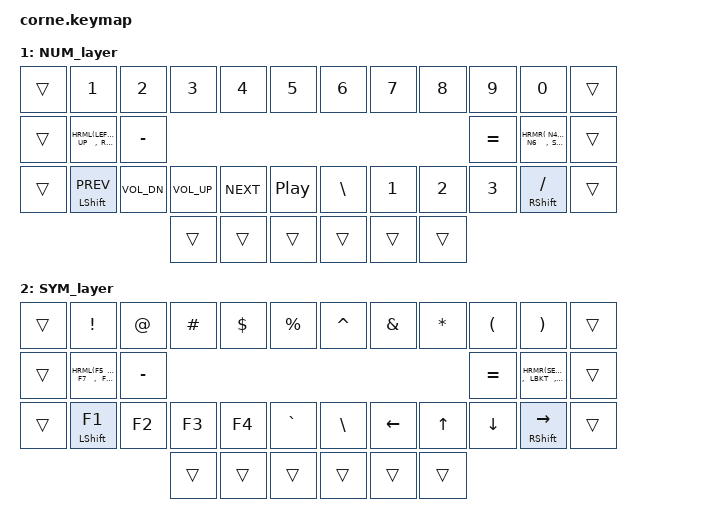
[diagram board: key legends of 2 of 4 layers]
// Copyright (c) 2022 The ZMK Contributors
// SPDX-License-Identifier: MIT

#include <behaviors.dtsi>
#include <dt-bindings/zmk/keys.h>
#include <dt-bindings/zmk/bt.h>



#define NUM 1
#define SYM 2
#define FNC 3


// funciones para acceso con hold ant tap
//#define HRML(k1,k2,k3,k4) &ht LSHFT k1  &ht LALT  k2  &ht LGUI  k3  &ht LCTRL  k4
//#define HRMR(k1,k2,k3,k4) &ht RCTRL  k1 &ht RGUI k2  &ht RALT k3  &ht RSHFT  k4

#define HRML(k1,k2,k3,k4) &ht LSHFT k1  &ht LCTRL  k2  &ht LALT  k3  &ht LGUI  k4
#define HRMR(k1,k2,k3,k4) &ht RGUI  k1 &ht RALT k2  &ht RCTRL k3  &ht RSHFT  k4

#define CAGL(k1,k2,k3) &ht LCTRL k1  &ht LALT k2  &ht LGUI  k3
#define CAGR(k1,k2,k3) &ht LGUI  k1  &ht LALT k2  &ht LCTRL  k3

// === Macros para acentos y ñ (macOS U.S.) ===
//1. Configuración de Tap Dance
/ {
    behaviors {
        // Define un comportamiento de Tap Dance para cada vocal y la ñ
        td_a: tap_dance_acute_a {
            compatible = "zmk,behavior-tap-dance";
            #binding-cells = <0>;
            tapping-term-ms = <250>; // Tiempo máximo entre taps
            bindings = <&kp A>, <&a_acute>; // 1 tap: a | 2 taps: á
        };
        // Tap Dance para A/Á (mayúsculas)
        td_MA: tap_dance_acute_MA {
            compatible = "zmk,behavior-tap-dance";
            #binding-cells = <0>;
            tapping-term-ms = <250>;
            bindings = <&kp LS(A)>, <&MA_acute>; // 1 tap: A | 2 taps: Á
        };
        td_e: tap_dance_acute_e {
            compatible = "zmk,behavior-tap-dance";
            #binding-cells = <0>;
            tapping-term-ms = <200>;
            bindings = <&kp E>, <&e_acute>;
        };
        // Tap Dance para E (mayúsculas)
        td_ME: tap_dance_acute_ME {
            compatible = "zmk,behavior-tap-dance";
            #binding-cells = <0>;
            tapping-term-ms = <200>;
            bindings = <&kp LS(E)>, <&ME_acute>;
        };
        td_i: tap_dance_acute_i {
            compatible = "zmk,behavior-tap-dance";
            #binding-cells = <0>;
            tapping-term-ms = <200>;
            bindings = <&kp I>, <&i_acute>;
        };
        // Tap Dance para I (mayúsculas)
        td_MI: tap_dance_acute_MI {
            compatible = "zmk,behavior-tap-dance";
            #binding-cells = <0>;
            tapping-term-ms = <200>;
            bindings = <&kp LS(I)>, <&MI_acute>;
        };
        td_o: tap_dance_acute_o {
            compatible = "zmk,behavior-tap-dance";
            #binding-cells = <0>;
            tapping-term-ms = <200>;
            bindings = <&kp O>, <&o_acute>;
        };
        // Tap Dance para O (mayúsculas)
        td_MO: tap_dance_acute_MO {
            compatible = "zmk,behavior-tap-dance";
            #binding-cells = <0>;
            tapping-term-ms = <200>;
            bindings = <&kp LS(O)>, <&MO_acute>;
        };
        td_u: tap_dance_acute_u {
            compatible = "zmk,behavior-tap-dance";
            #binding-cells = <0>;
            tapping-term-ms = <200>;
            bindings = <&kp U>, <&u_acute>;
        };
        // Tap Dance para U (mayúsculas)
        td_MU: tap_dance_acute_MU {
            compatible = "zmk,behavior-tap-dance";
            #binding-cells = <0>;
            tapping-term-ms = <200>;
            bindings = <&kp LS(U)>, <&MU_acute>;
        };
        td_n: tap_dance_tilde_n {
            compatible = "zmk,behavior-tap-dance";
            #binding-cells = <0>;
            tapping-term-ms = <200>;
            bindings = <&kp N>, <&n_tilde>; // 1 tap: n | 2 taps: ñ
        };
        // Tap Dance para N (mayúsculas)
        td_MN: tap_dance_acute_MN {
            compatible = "zmk,behavior-tap-dance";
            #binding-cells = <0>;
            tapping-term-ms = <200>;
            bindings = <&kp LS(N)>, <&MN_acute>;
        };
    };
};

//2. Define las macros para acentos y ñ
/ {
    macros {
        // Macro para á (Alt + E + A)
        a_acute: a_acute {
            compatible = "zmk,behavior-macro";
            #binding-cells = <0>;
            bindings = <&kp LA(E)>, <&kp A>;
        };
        // Macro para Á (Alt + E + Shift + a)
        MA_acute: MA_acute {
            compatible = "zmk,behavior-macro";
            #binding-cells = <0>;
            bindings = <&kp LA(E)>, <&kp LS(A)>; // LS = Left Shift
        };
        // Macro para é (Alt + E + E)
        e_acute: e_acute {
            compatible = "zmk,behavior-macro";
            #binding-cells = <0>;
            bindings = <&kp LA(E)>, <&kp E>;
        };
        // Macro para E 
        ME_acute: ME_acute {
            compatible = "zmk,behavior-macro";
            #binding-cells = <0>;
            bindings = <&kp LA(E)>, <&kp LS(E)>; // LS = Left Shift
        };
        // Macro para í (Alt + E + I)
        i_acute: i_acute {
            compatible = "zmk,behavior-macro";
            #binding-cells = <0>;
            bindings = <&kp LA(E)>, <&kp I>;
        };
        // Macro para I
        MI_acute: MI_acute {
            compatible = "zmk,behavior-macro";
            #binding-cells = <0>;
            bindings = <&kp LA(E)>, <&kp LS(I)>; // LS = Left Shift
        };
        // Macro para ó (Alt + E + O)
        o_acute: o_acute {
            compatible = "zmk,behavior-macro";
            #binding-cells = <0>;
            bindings = <&kp LA(E)>, <&kp O>;
        };
        // Macro para O
        MO_acute: MO_acute {
            compatible = "zmk,behavior-macro";
            #binding-cells = <0>;
            bindings = <&kp LA(E)>, <&kp LS(O)>; // LS = Left Shift
        };
        // Macro para ú (Alt + E + U)
        u_acute: u_acute {
            compatible = "zmk,behavior-macro";
            #binding-cells = <0>;
            bindings = <&kp LA(E)>, <&kp U>;
        };
        // Macro para U
        MU_acute: MU_acute {
            compatible = "zmk,behavior-macro";
            #binding-cells = <0>;
            bindings = <&kp LA(E)>, <&kp LS(U)>; // LS = Left Shift
        };
        // Macro para ñ (Alt + N + N)
        n_tilde: n_tilde {
            compatible = "zmk,behavior-macro";
            #binding-cells = <0>;
            bindings = <&kp LA(N)>, <&kp N>;
        };
        // Macro para Ñ
        MN_acute: MN_acute {
            compatible = "zmk,behavior-macro";
            #binding-cells = <0>;
            bindings = <&kp LA(N)>, <&kp LS(N)>; // LS = Left Shift
        };
    };
};
//3. Usa mod-morph para alternar entre minúsculas y mayúsculas
/ {
    behaviors {
        // Alterna entre Tap Dance de a/á y A/Á con Shift
        m_a: morph_acute_a {
            compatible = "zmk,behavior-mod-morph";
            #binding-cells = <0>;
            bindings = <&td_a>, <&td_MA>; // Sin Shift: a/á | Con Shift: A/Á
            mods = <(MOD_LSFT|MOD_RSFT)>;
        };
        // Alterna entre Tap Dance con Shift
        m_e: morph_acute_e {
            compatible = "zmk,behavior-mod-morph";
            #binding-cells = <0>;
            bindings = <&td_e>, <&td_ME>; // Sin Shift | Con Shift: 
            mods = <(MOD_LSFT|MOD_RSFT)>;
        };
        // Alterna entre Tap Dance con Shift
        m_i: morph_acute_i {
            compatible = "zmk,behavior-mod-morph";
            #binding-cells = <0>;
            bindings = <&td_i>, <&td_MI>; // Sin Shift | Con Shift: 
            mods = <(MOD_LSFT|MOD_RSFT)>;
        };
        // Alterna entre Tap Dance con Shift
        m_o: morph_acute_o {
            compatible = "zmk,behavior-mod-morph";
            #binding-cells = <0>;
            bindings = <&td_o>, <&td_MO>; // Sin Shift | Con Shift: 
            mods = <(MOD_LSFT|MOD_RSFT)>;
        };
        // Alterna entre Tap Dance con Shift
        m_u: morph_acute_u {
            compatible = "zmk,behavior-mod-morph";
            #binding-cells = <0>;
            bindings = <&td_u>, <&td_MU>; // Sin Shift | Con Shift: 
            mods = <(MOD_LSFT|MOD_RSFT)>;
        };
        // Alterna entre Tap Dance con Shift
        m_n: morph_acute_n {
            compatible = "zmk,behavior-mod-morph";
            #binding-cells = <0>;
            bindings = <&td_n>, <&td_MN>; // Sin Shift | Con Shift: 
            mods = <(MOD_LSFT|MOD_RSFT)>;
        };
    };
};


// === Macros para acentos y ñ (macOS U.S.) ===

//Ini prueba de tap
/ {
    behaviors {
        td0: tap_dance_0 {
            compatible = "zmk,behavior-tap-dance";
            #binding-cells = <0>;
            tapping-term-ms = <200>;
            bindings = <&kp N>, <&kp N2>, <&kp N3>;
        };
    };        
};

//Fin prueba de tap

//manejo del tab con letra Q
/ {
    behaviors {
        q_tab: q_tab {
            compatible = "zmk,behavior-tap-dance";
            #binding-cells = <0>;
            //flavor = "tap-unless-interrupted";  // Prioriza Tab, a menos que se combine con otra tecla
            tapping-term-ms = <200>;           // Tiempo para considerar un tap
            //quick-tap-ms = <0>;                // Desactiva el "quick tap"
            bindings = <&kp TAB>, <&kp Q>;     // Tap: Tab | Hold: Q
        };
    };
};

/ {
    macros {
        my_appl: my_appl {
            label = "ZM_my_appl";
            compatible = "zmk,behavior-macro";
            #binding-cells = <0>;
            wait-ms = <5>;
            tap-ms = <5>;
            bindings
                = <&macro_tap &kp C &kp S &kp A &kp N &kp H &kp U &kp E  &kp Z &kp A &kp A &kp AT &kp R &kp A &kp L &kp U &kp N &kp T &kp E &kp C &kp H &kp DOT &kp C &kp O &kp M>

                ;
        };
    };
};

/ {
    macros {
        rut_rpy: rut_rpy {
            label = "ZM_rut_rpy";
            compatible = "zmk,behavior-macro";
            #binding-cells = <0>;
            wait-ms = <5>;
            tap-ms = <5>;
            bindings
                = <&macro_tap &kp N8 &kp N3 &kp N3 &kp N8 &kp N2 &kp N7 &kp N0 &kp N0 &kp MINUS &kp N6>

                ;
        };
    };
};

/ {
    macros {
        my_p: my_p {
            label = "ZM_my_p";
            compatible = "zmk,behavior-macro";
            #binding-cells = <0>;
            wait-ms = <5>;
            tap-ms = <5>;
            bindings
                = <&macro_tap  &kp M  &kp A &kp U &kp R &kp N1 &kp N1>

                ;
        };
    };
};

/ {
    macros {
        my_m: my_m {
            label = "ZM_my_m";
            compatible = "zmk,behavior-macro";
            #binding-cells = <0>;
            wait-ms = <5>;
            tap-ms = <5>;
            bindings
                = <&macro_tap  &kp C  &kp R &kp S &kp A &kp L  &kp M &kp A &kp R &kp Z  &kp A &kp AT &kp G &kp M &kp A &kp I &kp L &kp DOT &kp C &kp O &kp M>

                ;
        };
    };
};

/ {
    macros {
        prueba: prueba {
            label = "ZM_prueba";
            compatible = "zmk,behavior-macro";
            #binding-cells = <0>;
           wait-ms = <10>;
            bindings
                = <&kp F &kp A &kp S &kp T>
                , <&macro_wait_time 500>
                , <&kp S &kp L &kp O &kp W>
            ;
        };
    };
};


/ {
    behaviors {
        ht: hold_tap {
            label = "hold_tap";
            compatible = "zmk,behavior-hold-tap";
            #binding-cells = <2>;
            flavor = "tap-preferred";
            tapping-term-ms = <220>;
            quick-tap-ms = <150>;
            global-quick-tap;
            bindings = <&kp>, <&kp>;
        };
    };

    conditional_layers {
        compatible = "zmk,conditional-layers";
        tri_layer {
            if-layers = <NUM SYM>;
            then-layer = <FNC>;
        };
    };



#define SYM_SPC  &lt SYM SPACE
//#define LCA_ENT  &mt LC(LALT) ENTER
#define SFT_ENT  &ht RSHFT ENTER
#define SFT_ESC  &ht RSHFT ESC
#define ALT_ESC  &ht LALT ESC
#define ALT_FSLH  &ht LALT FSLH
#define SFT_BSPC &ht RSHFT BSPC
#define ALT_BSPC &ht LALT BSPC
#define GUI_BSPC  &ht RGUI BSPC
//#define GUI_TAB  &ht RGUI LG(TAB)
#define GUI_ENT  &ht RGUI ENTER
#define GUI_SPC  &ht RGUI SPACE
#define CTL_TAB  &ht LCTRL TAB
#define CTL_ESC  &ht LCTRL ESC
#define CTL_ACUTE &ht LCTRL ACUTE
#define CTL_SPC  &ht RCTRL SPACE
#define SFT_Z  &ht LSHFT Z
#define SFT_A  &ht LSHFT  &m_a 


// los Shifts sobre capa NUM 
#define SFT_PRE  &ht LSHFT C_PREV
#define SFT_FSLH &ht RSHFT FSLH

// los Shifts sobre capa SYM
#define SFT_F1  &ht LSHFT F1
#define SFT_RGHT &ht RSHFT RIGHT



//#define PRE  &kp C_PREV
#define VDN  &kp C_VOL_DN
#define VUP  &kp C_VOL_UP
#define NXT  &kp C_NEXT
#define PLP  &kp C_PP

#define LFT  &kp LEFT
#define DWN  &kp DOWN
#define UPT  &kp UP
#define RHT  &kp RIGHT

//HRML(C_PREV   , C_VOL_DN , C_VOL_UP ,  C_NEXT  )
#define NUM_TAB  &lt NUM TAB
#define NUM_SPC  &lt NUM SPACE



    keymap {
        compatible = "zmk,keymap";
        default_layer {
            bindings = <
        //╭──────────┬──────────┬──────────┬──────────┬──────────╮   ╭──────────┬──────────┬──────────┬──────────┬──────────╮
        //│     Q    │    W     │    E é   │     R    │    T     │   │     Y    │    U ú   │    I í   │    O ó   │    P     │
&trans       &kp Q      &kp W       &m_e      &kp R      &kp T         &kp Y       &m_u        &m_i       &m_o       &kp P     &trans     
        //╰──────────╯──────────╯──────────╯──────────╯──────────╯   ╰──────────╯──────────╯──────────╯──────────╯──────────╯
        //│    A á   │    S ⌃   │    D ⌥   │   F ⌘    │  G       │   │     H    │    J ⌘   │    K ⌥   │    L ⌃   │    ⌫ ⌥   │
&trans      &m_a CAGL(    S     ,    D     ,   F      )  &kp G        &kp H CAGR(    J     ,    K     ,    L     )  ALT_BSPC   &trans     
        //╰──────────╯──────────╯──────────╯──────────╯──────────╯   ╰──────────╯──────────╯──────────╯──────────╯──────────╯
        //│    Z ⇧   │  X       │  C       │  V       │  B       │   │    N  ñ  │    M     │   , <    │   . >    │    ⏎ ⇧   │
 &trans     SFT_Z       &kp X      &kp C      &kp  V     &kp B           &m_n      &kp M     &kp COMMA   &kp DOT    SFT_ENT    &trans     
        //╰──────────╯──────────╯──────────╯──────────╯──────────╯   ╰──────────╯──────────╯──────────╯──────────╯──────────╯
        //                      │   ⎋ ⇧    │   ⇥ Num  │    ⏎ ⌘   │   │    ⇥ ⌃   │   ␣ Sym  │   /?¿    │ 
                                  SFT_ESC    NUM_TAB     GUI_ENT       CTL_TAB    SYM_SPC    ALT_FSLH
        //                      ╰──────────┴──────────┴──────────╯   ╰──────────┴──────────┴──────────╯
            >;
        };

        NUM_layer {
            bindings = <
        //╭──────────┬──────────┬──────────┬──────────┬──────────╮   ╭──────────┬──────────┬──────────┬──────────┬──────────╮   
        //│    1 !   │    2 @   │   3 #    │   4 $    │    5 %   │   │   6 ^    │  7 &     │  8 *     │  9 (     │   0 )    │   
&trans      &kp N1     &kp N2     &kp N3     &kp N4     &kp N5        &kp N6      &kp N7     &kp N8     &kp N9      &kp N0    &trans
        //╰──────────╯──────────╯──────────╯──────────╯──────────╯   ╰──────────╯──────────╯──────────╯──────────╯──────────╯  
        //│ LEFT     │  DOWN    │    UP    │  RIGHT   │  - _     │   │   = +    │  4 $     │  5 %     │  6 ^     │    ' "   │   
&trans     HRML(LEFT ,  DOWN    ,    UP    ,  RIGHT   ) &kp MINUS     &kp EQUAL  HRMR( N4  ,   N5     ,   N6     ,  SQT     )  &trans    
        //╰──────────╯──────────╯──────────╯──────────╯──────────╯   ╰──────────╯──────────╯──────────╯──────────╯──────────╯   
        //│   PREV   │  DOWN    │   UP     │   NEXT   │   MUTE   │   │   \ |    │  1 !     │  2 @     │  3 #     │  / ? ¿   │   
&trans      SFT_PRE      VDN        VUP        NXT        PLP          &kp BSLH    &kp N1     &kp N2     &kp N3    SFT_FSLH   &trans
        //╰──────────╯──────────╯──────────╯──────────╯──────────╯   ╰──────────╯──────────╯──────────╯──────────╯──────────╯  
//                              │   ⎋ ⇧    │          │    ⏎ ⌘   │   │    ⇥ ⌃   │   ␣ Sym  │   /?¿    │     
                                   &trans    &trans    &trans           &trans    &trans     &trans        
        //                      ╰──────────┴──────────┴──────────╯   ╰──────────┴──────────┴──────────╯
            >;    
        };

        SYM_layer {
            bindings = <
        //╭──────────┬──────────┬──────────┬──────────┬──────────╮   ╭──────────┬──────────┬──────────┬──────────┬──────────╮
        //│     !    │     @    │     #    │     $    │     %    │   │     ^    │     &    │     *    │     (    │     )    │
   &trans   &kp EXCL     &kp AT   &kp HASH   &kp DLLR   &kp PRCNT      &kp CARET  &kp AMPS   &kp ASTRK  &kp LPAR   &kp RPAR     &trans 
        //╰──────────╯──────────╯──────────╯──────────╯──────────╯   ╰──────────╯──────────╯──────────╯──────────╯──────────╯  
        //│   F5     │    F6    │    F6    │   F8     │    - _   │   │    = +   │    ; :   │   ' "    │    [ {   │   } ]    │
   &trans   HRML(F5  ,    F6    ,    F7    ,   F8     ) &kp MINUS      &kp EQUAL HRMR(SEMI  ,   SQT    ,   LBKT   ,    RBKT ) &trans 
        //╰──────────╯──────────╯──────────╯──────────╯──────────╯   ╰──────────╯──────────╯──────────╯──────────╯──────────╯  
        //│    F1    │    F2    │    F3    │    F4    │    ` ~   │   │    \ |   │    LFT   │    UP    │    DOWN  │  RIGHT   │
   &trans    SFT_F1    &kp F2     &kp F3     &kp F4     &kp GRAVE      &kp BSLH  &kp LEFT    &kp UP     &kp DOWN   SFT_RGHT   &trans 
        //╰──────────╯──────────╯──────────╯──────────╯──────────╯   ╰──────────╯──────────╯──────────╯──────────╯──────────╯ 
//                              │   ⎋ ⇧    │   ⇥ Num  │    ⏎ ⌘   │   │    ⇥ ⌃   │          │   /?¿    │    
                                    &trans    &trans     &trans         &trans     &trans     &trans
        //                      ╰──────────┴──────────┴──────────╯   ╰──────────┴──────────┴──────────╯
            >;
        };

        FNC_layer {
            bindings = <
        //╭──────────┬──────────┬──────────┬──────────┬──────────╮   ╭──────────┬──────────┬──────────┬──────────┬──────────╮
        //│ RESET    │          │  my_m    │  &my_p   │PROFILE 0 │   │PROFILE 3 │          │          │          │  RESET   │
&trans     &sys_reset  &trans     &my_appl    &my_p    &bt BT_SEL 0  &bt BT_SEL 3   &trans     &trans     &trans    &sys_reset &trans 
        //╰──────────╯──────────╯──────────╯──────────╯──────────╯   ╰──────────╯──────────╯──────────╯──────────╯──────────╯  
        //│BOOTLOADER│          │          │          │PROFILE 1 │   │PROFILE 4 │          │          │          │BOOTLOADER│
&trans    &bootloader  &trans     &trans     &trans    &bt BT_SEL 1  &bt BT_SEL 4   &trans     &trans     &trans   &bootloader  &trans 
        //╰──────────╯──────────╯──────────╯──────────╯──────────╯   ╰──────────╯──────────╯──────────╯──────────╯──────────╯  
        //│          │          │          │ CLEAR BT │PROFILE 2 │   │          │          │          │          │          │
&trans       &trans     &trans     &trans   &bt BT_CLR &bt BT_SEL 2    &trans     &trans     &trans     &trans     &trans  &trans 
        //╰──────────┴──────────┴──────────┼──────────┼──────────┤   ├──────────┼──────────┼──────────┴──────────┴──────────╯
//                              │   ⎋ ⇧    │          │    ⏎ ⌘   │   │    ⇥ ⌃   │          │   /?¿    │    
                                  &trans     &trans     &trans         &trans     &trans      &trans
        //                      ╰──────────┴──────────┴──────────╯   ╰──────────┴──────────┴──────────╯
            >;
        };
    };
};
